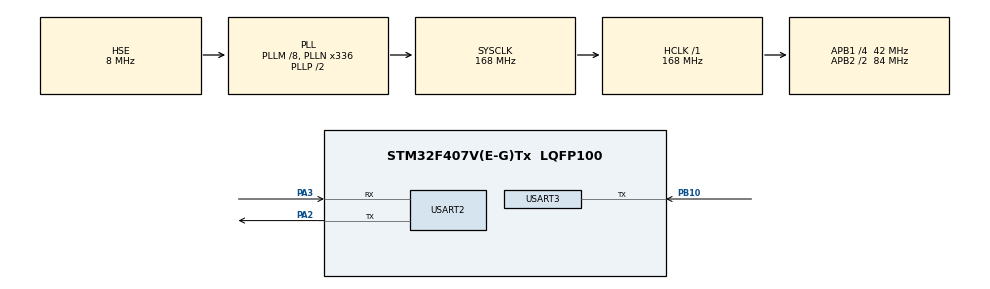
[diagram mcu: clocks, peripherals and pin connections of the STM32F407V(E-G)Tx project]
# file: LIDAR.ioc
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Dma.Request0=USART3_RX
Dma.USART3_RX.0.Direction=DMA_PERIPH_TO_MEMORY
Dma.USART3_RX.0.FIFOMode=DMA_FIFOMODE_DISABLE
Dma.USART3_RX.0.Instance=DMA1_Stream1
Dma.USART3_RX.0.MemDataAlignment=DMA_MDATAALIGN_BYTE
Dma.USART3_RX.0.MemInc=DMA_MINC_ENABLE
Dma.USART3_RX.0.Mode=DMA_CIRCULAR
Dma.USART3_RX.0.PeriphDataAlignment=DMA_PDATAALIGN_BYTE
Dma.USART3_RX.0.PeriphInc=DMA_PINC_DISABLE
Dma.USART3_RX.0.Priority=DMA_PRIORITY_HIGH
Mcu.Family=STM32F4
Mcu.Name=STM32F407V(E-G)Tx
Mcu.Package=LQFP100
NVIC.DMA1_Stream1_IRQn=true\:0\:0\:false\:false\:true\:false\:true\:true
NVIC.PriorityGroup=NVIC_PRIORITYGROUP_4
PA2.Mode=Asynchronous
PA2.Signal=USART2_TX
PA3.Mode=Asynchronous
PA3.Signal=USART2_RX
PB10.Mode=Half_duplex(single_wire_mode)
PB10.Signal=USART3_TX
PH0-OSC_IN.Mode=HSE-External-Oscillator
PH0-OSC_IN.Signal=RCC_OSC_IN
PH1-OSC_OUT.Mode=HSE-External-Oscillator
PH1-OSC_OUT.Signal=RCC_OSC_OUT
ProjectManager.HeapSize=0x200
ProjectManager.StackSize=0x400
ProjectManager.TargetToolchain=STM32CubeIDE
RCC.48MHZClocksFreq_Value=84000000
RCC.AHBFreq_Value=168000000
RCC.APB1CLKDivider=RCC_HCLK_DIV4
RCC.APB1Freq_Value=42000000
RCC.APB1TimFreq_Value=84000000
RCC.APB2CLKDivider=RCC_HCLK_DIV2
RCC.APB2Freq_Value=84000000
RCC.APB2TimFreq_Value=168000000
RCC.CortexFreq_Value=168000000
RCC.HCLKFreq_Value=168000000
RCC.HSE_VALUE=8000000
RCC.HSI_VALUE=16000000
RCC.LSE_VALUE=32768
RCC.PLLM=8
RCC.PLLN=336
RCC.PLLSourceVirtual=RCC_PLLSOURCE_HSE
RCC.SYSCLKFreq_VALUE=168000000
RCC.SYSCLKSource=RCC_SYSCLKSOURCE_PLLCLK
RCC.VCOOutputFreq_Value=336000000
USART2.VirtualMode=VM_ASYNC
USART3.Mode=MODE_RX
USART3.VirtualMode=VM_ASYNC
board=custom

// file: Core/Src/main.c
/* USER CODE BEGIN Header */
/**
 ******************************************************************************
 * @file           : main.c
 * @brief          : Main program body
 ******************************************************************************
 * @attention
 *
 * Copyright (c) 2025 STMicroelectronics.
 * All rights reserved.
 *
 * This software is licensed under terms that can be found in the LICENSE file
 * in the root directory of this software component.
 * If no LICENSE file comes with this software, it is provided AS-IS.
 *
 ******************************************************************************
 */
/* USER CODE END Header */
#include "main.h"
#include "dma.h"
#include "usart.h"
#include "gpio.h"

/* USER CODE BEGIN Includes */
#include "driver_YLIDARX2.h"
#include <stdio.h>
#include <string.h>

/* USER CODE END Includes */

/* USER CODE BEGIN PTD */
typedef struct {
	float angle;      // en degrés
	uint16_t distance; // en mm
} LidarPoint;
/* USER CODE END PTD */

/* USER CODE BEGIN PD */
#define RX_BUFFER_SIZE 128  // taille du buffer DMA

/* USER CODE END PD */

/* USER CODE BEGIN PM */
h_YLIDARX2_t lidar; // Objet LIDAR
/* USER CODE END PM */

/* USER CODE BEGIN PV */

uint8_t rxBuffer[RX_BUFFER_SIZE];

/* USER CODE END PV */

void SystemClock_Config(void);

/* USER CODE BEGIN 0 */
int __io_putchar(int ch)
{
	HAL_UART_Transmit(&huart2, (uint8_t *)&ch, 1, HAL_MAX_DELAY);
	return ch;
}

// Callback DMA pour réception UART
void HAL_UART_RxCpltCallback(UART_HandleTypeDef *huart)
{
    if (huart->Instance == USART3)
    {
        // Ajouter chaque octet reçu au buffer du Lidar
        YLIDARX2_UART_irq(&lidar);

        // Relancer la réception DMA pour le prochain octet
        HAL_UART_Receive_DMA(&huart3, rxBuffer, 1);
    }
}

void HAL_UART_ErrorCallback(UART_HandleTypeDef *huart)
{
	if(huart->Instance == USART3)
	{
		if(HAL_UART_GetError(huart) & HAL_UART_ERROR_PE)
			printf("Parity Error!\r\n");
		if(HAL_UART_GetError(huart) & HAL_UART_ERROR_NE)
			printf("Noise Error!\r\n");
		if(HAL_UART_GetError(huart) & HAL_UART_ERROR_FE)
			printf("Framing Error!\r\n");
		if(HAL_UART_GetError(huart) & HAL_UART_ERROR_ORE)
			printf("Overrun Error!\r\n");
	}
}

/* USER CODE END 0 */

int main(void)
{

  /* MCU Configuration--------------------------------------------------------*/

  /* Reset of all peripherals, Initializes the Flash interface and the Systick. */
  HAL_Init();

  /* Configure the system clock */
  SystemClock_Config();

  /* Initialize all configured peripherals */
  MX_GPIO_Init();
  MX_DMA_Init();
  MX_USART2_UART_Init();
  MX_USART3_UART_Init();
  /* USER CODE BEGIN 2 */
	 printf("\r\n***** TEST LIDAR STM32F407 *****\r\n");

	    // Initialiser la structure Lidar
	    memset(&lidar, 0, sizeof(h_YLIDARX2_t));
	    lidar.uart_buffer = rxBuffer;

	    // Lancer la réception DMA 1 octet à la fois
	    HAL_UART_Receive_DMA(&huart3, rxBuffer, 1);

  /* USER CODE END 2 */

  /* Infinite loop */
	while (1)
	{

}
}

void SystemClock_Config(void)
{
  RCC_OscInitTypeDef RCC_OscInitStruct = {0};
  RCC_ClkInitTypeDef RCC_ClkInitStruct = {0};

  /** Configure the main internal regulator output voltage
  */
  __HAL_RCC_PWR_CLK_ENABLE();
  __HAL_PWR_VOLTAGESCALING_CONFIG(PWR_REGULATOR_VOLTAGE_SCALE1);

  /** Initializes the RCC Oscillators according to the specified parameters
  * in the RCC_OscInitTypeDef structure.
  */
  RCC_OscInitStruct.OscillatorType = RCC_OSCILLATORTYPE_HSE;
  RCC_OscInitStruct.HSEState = RCC_HSE_ON;
  RCC_OscInitStruct.PLL.PLLState = RCC_PLL_ON;
  RCC_OscInitStruct.PLL.PLLSource = RCC_PLLSOURCE_HSE;
  RCC_OscInitStruct.PLL.PLLM = 8;
  RCC_OscInitStruct.PLL.PLLN = 336;
  RCC_OscInitStruct.PLL.PLLP = RCC_PLLP_DIV2;
  RCC_OscInitStruct.PLL.PLLQ = 4;
  if (HAL_RCC_OscConfig(&RCC_OscInitStruct) != HAL_OK)
  {
    Error_Handler();
  }

  /** Initializes the CPU, AHB and APB buses clocks
  */
  RCC_ClkInitStruct.ClockType = RCC_CLOCKTYPE_HCLK|RCC_CLOCKTYPE_SYSCLK
                              |RCC_CLOCKTYPE_PCLK1|RCC_CLOCKTYPE_PCLK2;
  RCC_ClkInitStruct.SYSCLKSource = RCC_SYSCLKSOURCE_PLLCLK;
  RCC_ClkInitStruct.AHBCLKDivider = RCC_SYSCLK_DIV1;
  RCC_ClkInitStruct.APB1CLKDivider = RCC_HCLK_DIV4;
  RCC_ClkInitStruct.APB2CLKDivider = RCC_HCLK_DIV2;

  if (HAL_RCC_ClockConfig(&RCC_ClkInitStruct, FLASH_LATENCY_5) != HAL_OK)
  {
    Error_Handler();
  }
}

void Error_Handler(void)
{
	__disable_irq();
	while (1)
	{
	}
}
